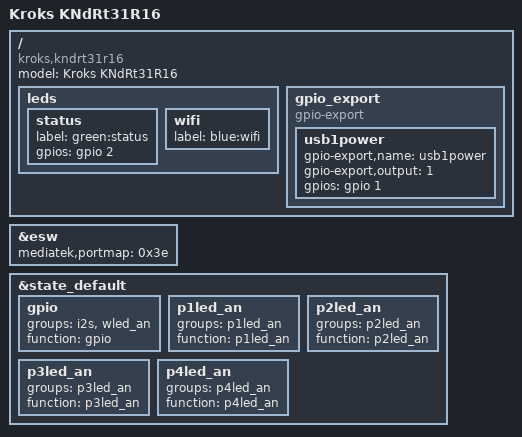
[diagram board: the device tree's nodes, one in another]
// SPDX-License-Identifier: GPL-2.0-or-later OR MIT

#include "mt7628an_kroks.dtsi"

/ {
	compatible = "kroks,kndrt31r16", "mediatek,mt7628an-soc";
	model = "Kroks KNdRt31R16";

	leds {
		status {
			label = "green:status";
			gpios = <&gpio 2 GPIO_ACTIVE_HIGH>;
		};

		wifi {
			label = "blue:wifi";
		};
	};

	gpio_export {
		compatible = "gpio-export";
		#size-cells = <0>;

		usb1power {
			gpio-export,name = "usb1power";
			gpio-export,output = <1>;
			gpios = <&gpio 1 GPIO_ACTIVE_HIGH>;
		};
	};
};

&esw {
	mediatek,portmap = <0x3e>;
};

&state_default {
	gpio {
		groups = "i2s", "wled_an";
		function = "gpio";
	};

	p1led_an {
		groups = "p1led_an";
		function = "p1led_an";
	};

	p2led_an {
		groups = "p2led_an";
		function = "p2led_an";
	};

	p3led_an {
		groups = "p3led_an";
		function = "p3led_an";
	};

	p4led_an {
		groups = "p4led_an";
		function = "p4led_an";
	};
};
